# PCIE_PORT_LOGIC_REGS register map
Vendor: Texas Instruments
Peripheral module from a debugger description file (folder 66AK2G0x_66AK2G1x).
Registers are 32-bit, access per field, reset 0x0 unless marked. A register's access mark holds for its fields unless they carry their own. Offsets are as the file gives them; lines under a group give offsets from that group; [hi:lo] are bit positions; {n}, {i} and the like mark numbered series; 'fields as' and 'values as' point back to an identical list; <NAME> marks a mode.

## PCIE_PORT_LOGIC_REGS
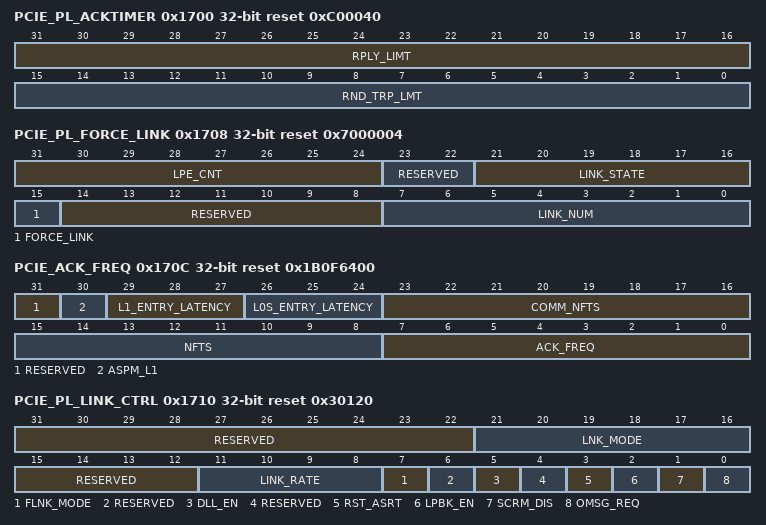
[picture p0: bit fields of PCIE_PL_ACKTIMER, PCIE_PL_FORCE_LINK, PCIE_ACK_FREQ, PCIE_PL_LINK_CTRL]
0x1700 PCIE_PL_ACKTIMER rw reset 0xC00040
  [31:16] RPLY_LIMT — Replay Time Limit. The replay timer expires when it reaches this limit.
  [15:0] RND_TRP_LMT — Round Trip Latency Time Limit. The Ack/Nak latency timer expires when it reaches this limit.
0x1704 PCIE_PL_OMSG rw reset 0xFFFFFFFF
  [31:0] OMSG — Other Message Register. It can be used to send a specific PCI Express message in which case this register is programmed with the payload and bit 0 of Port Link Control Register is set to transmit the message.
0x1708 PCIE_PL_FORCE_LINK access not given reset 0x7000004
  [31:24] LPE_CNT rw — Low Power Entrance Count
  [23:22] RESERVED ro — Reads return 0 and writes have no effect.
  [21:16] LINK_STATE rw — Link State. The link state that the PCIe will be forced to when FORCE_LINK field is set. Please seefor LTSSM states encoded values.
  [15] FORCE_LINK — Force Link. Forces the link to the state specified by the LINK_STATE field. The Force Link pulse will trigger link re-negotiation. (access W1S)
  [14:8] RESERVED ro — Reads return 0 and writes have no effect.
  [7:0] LINK_NUM rw — Link Number. Not used for EP.
0x170C PCIE_ACK_FREQ reset 0x1B0F6400
  [31] RESERVED ro — Reads return 0 and writes have no effect.
  [30] ASPM_L1 rw — Set to allow entering ASPM L1 even when link partner did not to L0s. When cleared, the ASPM L1 state is entered only after idle period during which both RX and TX are in L0s.
  [29:27] L1_ENTRY_LATENCY rw — L1 entrance latency. The latency is set to 2^L1_ENTRY_LATENCY microseconds with the max being 64 microseconds.
  [26:24] L0S_ENTRY_LATENCY rw — L0s entrance latency. The latency is set to L0S_ENTRY_LATENCY+1 microseconds. Maximum is 7 microseconds.
  [23:16] COMM_NFTS rw — Number of fast training sequences when common clock is used and when transitioning from L0s to L0.
  [15:8] NFTS rw — Number of fast training sequences to be transmitted when transitioning from L0s to L0. Value of 0is not supported.
  [7:0] ACK_FREQ rw — Ack Frequency. The value range is 0x0-0xFF. A value of 0 in the ACK Frequency field indicates that this ACK frequency control feature is disabled. A value of N (N&gt;0) indicates that the module will ack N TLPs received by sending an ACK DLLP.
0x1710 PCIE_PL_LINK_CTRL reset 0x30120
  [31:22] RESERVED ro — Reads return 0 and writes have no effect.
  [21:16] LNK_MODE rw — Link Mode Enable. (×N – corresponding to N Lanes).
  [15:12] RESERVED ro — Reads return 0 and writes have no effect.
  [11:8] LINK_RATE rw — Default link rate. For 2.5 GT/s it is 0x1. This register does not affect any functionality.
  [7] FLNK_MODE rw — Fast link mode. Set all internal timers to fast mode for simulation purposes.
  [6] RESERVED ro — Reads return 0 and writes have no effect.
  [5] DLL_EN rw — DLL Link Enable. Enable link initialization.
  [4] RESERVED ro — Reads return 0 and writes have no effect.
  [3] RST_ASRT rw — Reset assert. Triggers a recovery and forces the LTSSM to the Hot Reset state. Downstream ports (RC ports) only.
  [2] LPBK_EN rw — Loopback Enable. Turn on loopback.
  [1] SCRM_DIS rw — Scramble Disable. Turn off data scrambling.
  [0] OMSG_REQ rw — Other message request. Set to transmit the message contained in the Other Message Register (PCIE_PL_OMSG).
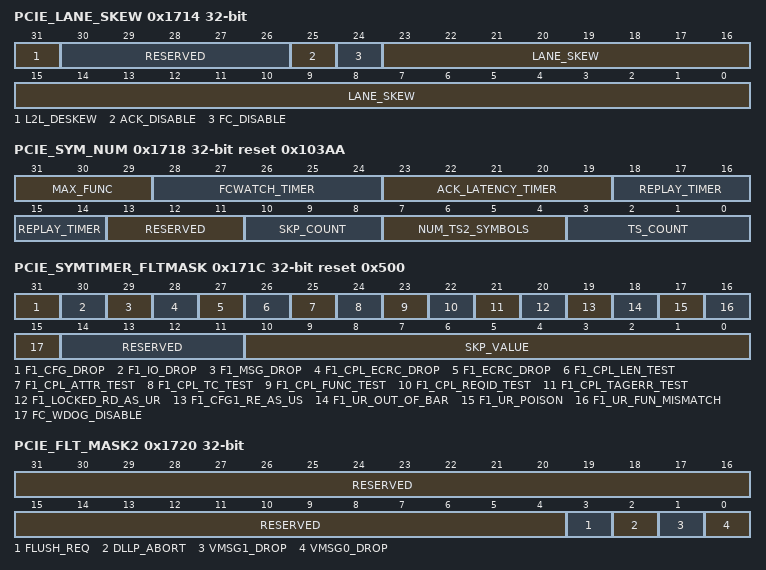
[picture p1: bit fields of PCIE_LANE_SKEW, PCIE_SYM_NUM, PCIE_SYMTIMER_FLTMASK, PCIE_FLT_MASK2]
0x1714 PCIE_LANE_SKEW
  [31] L2L_DESKEW rw — Disable Lane to Lane Deskew.
  [30:26] RESERVED ro — Reads return 0 and writes have no effect.
  [25] ACK_DISABLE rw — Disable Ack and Nak DLLP transmission.
  [24] FC_DISABLE rw — Flow Control Disable. Set to disable transmission of Flow Control DLLPs.
  [23:0] LANE_SKEW rw — Insert Lane Skew for Transmit. The value is in units of one symbol time. Thus a value 0x02 will force a skew of two symbol times for that lane. Max allowed is 5 symbol times. This 24 bit field is used for programming skew for eight lanes with three bits per lane.
0x1718 PCIE_SYM_NUM reset 0x103AA
  [31:29] MAX_FUNC rw — Configuration requests targeted at function numbers above this value will result in UR response.
  [28:24] FCWATCH_TIMER rw — Timer Modifier for Flow Control Watchdog Timer. Increases the timer value for Flow Control watchdog timer in increments of 16 clock cycles.
  [23:19] ACK_LATENCY_TIMER rw — Timer Modifier for Ack/Nak Latency Timer. Increases the timer value for the Ack/Nak latency timer in increments of 64 clock cycles.
  [18:14] REPLAY_TIMER rw — Timer Modifier for Replay Timer. Increases the timer value for the replay timer in increments of 64 clock cycles.
  [13:11] RESERVED ro — Reads return 0 and writes have no effect.
  [10:8] SKP_COUNT rw — Number of SKP Symbols.
  [7:4] NUM_TS2_SYMBOLS rw — Number of TS2 Symbols. This field does not affect any functionality.
  [3:0] TS_COUNT rw — Number of TS Symbols. Set the number of TS identifier symbols that are sent in TS1 and TS2 ordered sets.
0x171C PCIE_SYMTIMER_FLTMASK reset 0x500
  [31] F1_CFG_DROP rw — Set to allow CFG TLPs on RC
  [30] F1_IO_DROP rw — Set to allow IO TLPs on RC
  [29] F1_MSG_DROP rw — Set to allow MSG TLPs on RC
  [28] F1_CPL_ECRC_DROP rw — Set to allow Completion TLPs with ECRC to pass up
  [27] F1_ECRC_DROP rw — Set to allow TLPs with ECRC error to pass up
  [26] F1_CPL_LEN_TEST rw — Set to mask length match for received completion TLPs
  [25] F1_CPL_ATTR_TEST rw — Set to mask attribute match on received completion TLPs
  [24] F1_CPL_TC_TEST rw — Set to mask traffic match on received completion TLPs
  [23] F1_CPL_FUNC_TEST rw — Set to mask function match on received completion TLPs
  [22] F1_CPL_REQID_TEST rw — Set to mask request ID match on received completion TLPs
  [21] F1_CPL_TAGERR_TEST rw — Set to mask tag error rules for received completion TLPs
  [20] F1_LOCKED_RD_AS_UR rw — Set to treat locked read TLPs as supported for EP, UR for RC
  [19] F1_CFG1_RE_AS_US rw — Set to treat type 1 CFG TLPs as supported for EP, UR for RC
  [18] F1_UR_OUT_OF_BAR rw — Set to treat out-of-BAR TLPs as supported requests
  [17] F1_UR_POISON rw — Set to treat poisoned TLPs as supported requests
  [16] F1_UR_FUN_MISMATCH rw — Set to treat function mismatched TLPs as supported requests
  [15] FC_WDOG_DISABLE rw — Set to disable FC watchdog timer
  [14:11] RESERVED ro — Reads return 0 and writes have no effect.
  [10:0] SKP_VALUE rw — Number of symbol times to wait between transmitting SKP ordered sets. For example, for a setting of 1536 decimal, the wait will be for 1537 symbol times.
0x1720 PCIE_FLT_MASK2
  [31:4] RESERVED ro — Reads return 0 and writes have no effect.
  [3] FLUSH_REQ rw — Set to enable the filter to handle flush request
  [2] DLLP_ABORT rw — Set to disable DLLP abort for unexpected CPL
  [1] VMSG1_DROP rw — Set to disable dropping of Vendor MSG Type 1
  [0] VMSG0_DROP rw — Set to disable dropping of Vendor MSG Type 0 with UR reporting
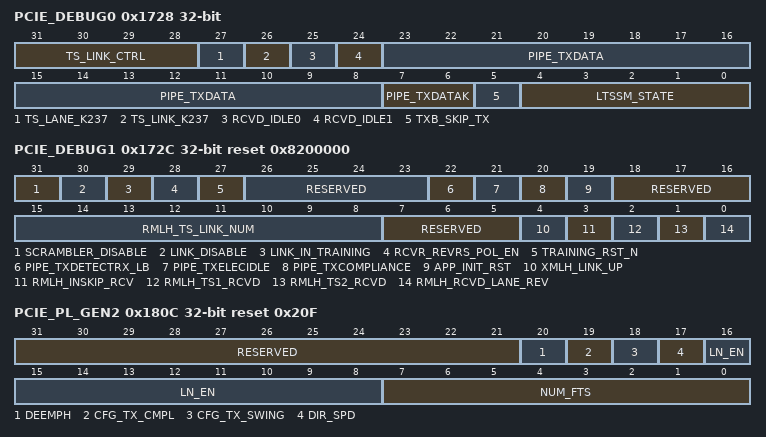
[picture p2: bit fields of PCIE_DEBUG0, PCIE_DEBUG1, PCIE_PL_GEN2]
0x1728 PCIE_DEBUG0 ro
  [31:28] TS_LINK_CTRL — Link control bits advertised by link partner.
  [27] TS_LANE_K237 — Currently receiving k237 (PAD) in place of lane number.
  [26] TS_LINK_K237 — Currently receiving k237 (PAD) in place of link number.
  [25] RCVD_IDLE0 — Receiver is receiving logical idle.
  [24] RCVD_IDLE1 — 2nd symbol is also idle (16bit PHY interface only).
  [23:8] PIPE_TXDATA — PIPE Transmit data. Reset value is zero but changes at every clock after that.
  [7:6] PIPE_TXDATAK — PIPE transmit K indication.
  [5] TXB_SKIP_TX — A skip ordered set has been transmitted.
  [4:0] LTSSM_STATE — LTSSM current state. Please see for the names of the LTSSM states corresponding to the encoded values.
0x172C PCIE_DEBUG1 ro reset 0x8200000
  [31] SCRAMBLER_DISABLE — Scrambling disabled for the link.
  [30] LINK_DISABLE — LTSSM in DISABLE state. Link inoperable.
  [29] LINK_IN_TRAINING — LTSSM performing link training.
  [28] RCVR_REVRS_POL_EN — LTSSM testing for polarity reversal.
  [27] TRAINING_RST_N — LTSSM-negotiated link reset.
  [26:23] RESERVED — Reads return 0 and writes have no effect.
  [22] PIPE_TXDETECTRX_LB — PIPE receiver detect/loopback request.
  [21] PIPE_TXELECIDLE — PIPE transmit electrical idle request.
  [20] PIPE_TXCOMPLIANCE — PIPE transmit compliance request.
  [19] APP_INIT_RST — Application request to initiate training reset.
  [18:16] RESERVED — Reads return 0 and writes have no effect.
  [15:8] RMLH_TS_LINK_NUM — Link number advertised/confirmed by link partner.
  [7:5] RESERVED — Reads return 0 and writes have no effect.
  [4] XMLH_LINK_UP — LTSSM reports PHY link up.
  [3] RMLH_INSKIP_RCV — Receiver reports skip reception.
  [2] RMLH_TS1_RCVD — TS1 training sequence received (pulse).
  [1] RMLH_TS2_RCVD — TS2 training sequence received (pulse).
  [0] RMLH_RCVD_LANE_REV — Receiver detected lane reversal.
0x180C PCIE_PL_GEN2 reset 0x20F
  [31:21] RESERVED ro — Reads return 0 and writes have no effect.
  [20] DEEMPH rw — Set de-emphasis level for upstream ports (EP ports).
  [19] CFG_TX_CMPL rw — Configure TX compliance receive bit. When set to 1, signals LTSSM to transmit TS ordered sets with the compliance receive bit assert (equal to 1).
  [18] CFG_TX_SWING rw — Configure PHY TX Swing. Indicates the voltage level the PHY should drive.
  [17] DIR_SPD rw — Directed Speed Change.
  [16:8] LN_EN rw — Lane Enable.
  [7:0] NUM_FTS rw — Number of fast training sequences.
